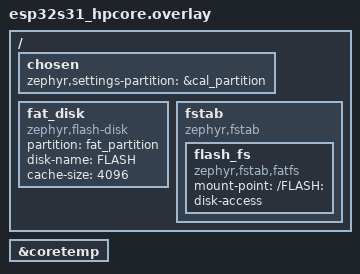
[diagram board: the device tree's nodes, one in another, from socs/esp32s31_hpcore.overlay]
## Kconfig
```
# SPDX-License-Identifier: GPL-3.0-or-later

mainmenu "multiapp: one firmware that runs the others"

config MULTIAPP_INSTR_HEAP_KB
	int "Extension code heap in PSRAM, KiB"
	default 1344

config MULTIAPP_DATA_HEAP_KB
	int "Extension data heap in PSRAM, KiB"
	default 1024
	help
	  The extensions' data, read-only data and bss, and llext's metadata.

config MULTIAPP_MODULE_HEAP_SIZE
	int "Internal RAM for the modules that run from it, bytes"
	default 8192 if SOC_SERIES_ESP32S31
	default 35840
	help
	  IRAM_ATTR code, data and bss of the modules built INTERNAL: below ring
	  bank 0 (src/apps.c), where a size that does not fit fails the host's
	  link. The Wi-Fi boots need the most: wifi and phy, about 33.4 KB. coex
	  also loads sdr (43 KB in all), which goes into dump bank 2 (BANK2,
	  doc/apps/multiapp-internals.md).

config MULTIAPP_MODULE_HIGH_HEAP_SIZE
	int "Bytes of the high region for a module's bss"
	# The ESP32-S31 has no high region: a token heap.
	default 256 if SOC_SERIES_ESP32S31
	default 14528
	help
	  The rest of the high region next to the area, for the bss of a module
	  built INTERNAL HIGH_BSS. A size that does not fit fails the host's link.

config MULTIAPP_MODULE_TESTS
	bool "The module loader's test modules"
	help
	  hello also needs hellolib in PSRAM, which needs hellofast in internal
	  RAM: the commands "hello mod" and "hello phy".

config MULTIAPP_STACK_SIZE
	int "Largest stack of an app's main() thread"
	default 4096
	help
	  One stack in PSRAM for every app's main(); an app that asks for more
	  (multiapp_extension() STACK) is refused.

# A default, not an assignment: the wifi module's Kconfig pass turns on what this depends on being off.
config ESP_SDR_PHY_ONLY
	default y

config MULTIAPP_SIGNED_EXTENSIONS
	bool "The sysbuild signs with the project's own key (SB_CONFIG_ESDR_SIGNING): extension files must be signed"
	depends on SOC_SERIES_ESP32S31
	help
	  Set by apps/common/sysbuild/signing.cmake. Then a key the build cannot use for the extension
	  signatures (not ED25519, unreadable) stops the build: accepting unsigned extensions in a build whose
	  image is signed would make the signature check a decoration.

config MULTIAPP_UNLOAD
	bool "Switch apps in place, unloading the running one"
	default y if SOC_SERIES_ESP32S3 || SOC_SERIES_ESP32S31
	select THREAD_MONITOR
	select SYS_HEAP_RUNTIME_STATS
	help
	  "multiapp run" stops the running app, unloads it and the modules the next one does not
	  need (the Wi-Fi driver, the SDR) and loads the next, when the two boots are compatible
	  (same USB profile, no console app). Otherwise, and when anything refuses to stop, it
	  reboots into the next app. Exercised on hardware on the ESP32-S3; the ESP32-S31 builds
	  with it, its radio module's down path is not yet tried on a board.

config MULTIAPP_STOP_TIMEOUT_MS
	int "How long an app's main() may take to end before the switch gives up"
	default 5000
	depends on MULTIAPP_UNLOAD

config MULTIAPP_STAGES
	bool "Hot-swap a DSP stage of the running app (development)"
	default y if SOC_SERIES_ESP32S3 || SOC_SERIES_ESP32S31
	depends on MULTIAPP_UNLOAD
	help
	  An app declares stages (include/multiapp/stage.h, MULTIAPP_STAGE_DEFINE()); "multiapp stage"
	  loads a small kernel (multiapp_kernel() in CMakeLists.txt, a file uploaded over the shell
	  or read from the volume) into the running app and swaps one stage to it at the app's
	  quiescent point, then unloads the old kernel, all without a reboot
	  (doc/apps/multiapp-internals.md, "Hot-swapping a stage"; apps/multiapp/scripts/kswap.py).
	  A development feature: it runs code of your choosing, so it belongs off in a product.

config MULTIAPP_STAGE_TIMEOUT_MS
	int "How long a swap waits for the app's sync point, ms"
	default 2000
	depends on MULTIAPP_STAGES
	help
	  After it the request is taken back, the new kernel unloaded and the shell says that the app
	  never got there. The shell commands take another value as a last argument.

config MULTIAPP_KERNEL_MAX_KB
	int "Largest kernel file, KiB"
	default 16
	depends on MULTIAPP_STAGES
	help
	  The PSRAM buffer an upload or a file is read into before llext copies it.

config MULTIAPP_KERNELS_IN_VOLUME
	bool "The kernels' files also go into the FAT volume image"
	depends on MULTIAPP_STAGES
	help
	  For "multiapp stage load" without a copy first; the kernels are never in multiapp_embedded[]
	  and never change the build id of the apps' files.

config MULTIAPP_WIFI
	bool "The stock Wi-Fi driver as a module"
	depends on DT_HAS_ESPRESSIF_ESP32_WIFI_ENABLED
	depends on ZEPHYR_HAL_ESPRESSIF_MODULE_BLOBS
	select WIFI
	select WIFI_USE_NATIVE_NETWORKING
	select NET_L2_WIFI_MGMT
	select NET_L2_ETHERNET_MGMT
	select THREAD_CUSTOM_DATA
	select EVENTS
	select THREAD_STACK_INFO
	help
	  The driver and its blobs are a module, wifi.llext on the volume, which
	  only the boots of an app that needs it load. The host has its
	  network interface (src/wifi_netif.c), down in every other boot, and
	  what the driver needs from the kernel and the network stack.

config MULTIAPP_MICROPYTHON
	bool "MicroPython as an app"
	depends on ZEPHYR_MICROPYTHON_MODULE
	help
	  The port, its C modules and frozen Python are one extension,
	  micropython.llext on the volume (micropython.cmake). The host keeps
	  what they need from the kernel, /FLASH: and the USB device; "multiapp
	  run micropython" reboots into its REPL on the CDC-ACM port.

config MULTIAPP_MICROPYTHON_GUI
	bool "MicroPython with a display"
	depends on MULTIAPP_MICROPYTHON
	help
	  Its extension also builds LVGL and the drivers of the board's display,
	  input devices and SD card, and freezes the launcher's apps. The
	  devicetree must have the board's peripherals; the host has no driver
	  for them.

config MULTIAPP_OSMOSDR_HS_LOAD_LOG
	bool "osmosdr_hs logs the CPU its stream leaves (a bench)"
	depends on SOC_SERIES_ESP32S31
	help
	  osmosdr_hs with its loadlog.conf, as its standalone bench build: a low
	  priority thread counts what it gets, and the log has it every 10 s.

config MULTIAPP_EMBEDDED
	bool "Apps built into the image too"
	default y
	help
	  Each app is also built into the image, loaded when the FAT volume has
	  no good file for it. Without, an app runs only from its file.

config MULTIAPP_FILE_MAX_KB
	int "Largest app file, KiB"
	default 2048
	help
	  The PSRAM buffer a boot reads the app's file into before loading it.

config MULTIAPP_AREA_SIZE
	int "Bytes of internal RAM the apps share, one per boot"
	# No app on the ESP32-S31 has buffers in the area.
	default 16 if SOC_SERIES_ESP32S31
	default 24128
	help
	  In the high region: the buffers an app defines with
	  ESP_SDR_HIGH_BUF_DEFINE() and ESP_SDR_HIGH_STACK_DEFINE() (osmosdr's
	  USB blocks, ring and USB thread stacks), or in other boots the 802.15.4
	  driver's buffers.

config MULTIAPP_RUNNING_AFTER_MS
	int "Mark an app as running once its main() has run this long, ms"
	default 3000
	help
	  A boot that dies on the way to its app is skipped once, to end a crash loop: the record of how
	  far it got (src/apps.c) says "running" when main() returns. An app whose main() never
	  returns (osmosdr_hs) would stay "in main" for ever, and a warm reboot would skip its autostart
	  once. This many milliseconds after main() starts, with the app still the one that started,
	  the record says "running" too; an app that dies earlier stays a crash-loop suspect. 0:
	  only when main() returns.

config MULTIAPP_AUTOSTART
	string "App to start at boot"
	default ""
	help
	  Started when no "multiapp run" request is pending from before a reset.
	  Empty: none, start one with "multiapp run <name>".

config LLEXT_EXPORT_SYMBOL_GROUP_MULTIAPP
	def_bool y
	help
	  What the embedded extensions import, exported by exports.py. Zephyr's
	  default groups (every syscall, a libc subset) stay off: what they
	  export is kept by the linker, kernel code in IRAM included.

# USB shell and DFU.
rsource "../common/Kconfig"
source "samples/subsys/usb/common/Kconfig.sample_usbd"

source "Kconfig.zephyr"
```

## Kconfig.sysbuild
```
# SPDX-License-Identifier: GPL-3.0-or-later

# The own signing key defaults (the ESP32-S31 CoreBoard), ahead of sysbuild's.
rsource "../common/sysbuild/Kconfig.signing"

source "share/sysbuild/Kconfig"
```

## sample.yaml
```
sample:
  name: ESP-SDR multiapp
  description: >-
    One firmware that runs the other apps as loadable extensions
    (doc/apps/multiapp-internals.md): capture, rfprobe, wpan, stream, osmosdr and link,
    loaded from files on a FAT volume, with built-in copies
common:
  tags: esp-sdr
  sysbuild: true
  # Each scenario names its integration board: twister would add a list here to every scenario's,
  # and the S31 one cannot have the XIAO.
tests:
  # The console is on USB CDC-ACM; "multiapp run <name>" there (see README).
  sample.esp_sdr.multiapp:
    platform_allow:
      - xiao_esp32s3/esp32s3/procpu
      - communicator_badge/esp32s3/procpu
      - esp32s31_function_coreboard/esp32s31/hpcore
    build_only: true
    integration_platforms:
      - xiao_esp32s3/esp32s3/procpu
  # On the desk with the boards attached (pytest/test_multiapp.py): the image and
  # its FAT volume (scripts/twister-flash.py), booting into hello from its file.
  sample.esp_sdr.multiapp.hil:
    platform_allow:
      - xiao_esp32s3/esp32s3/procpu
      - communicator_badge/esp32s3/procpu
    harness: pytest
    harness_config:
      pytest_dut_scope: module
      pytest_root:
        - pytest/test_multiapp.py
    extra_args:
      - multiapp_EXTRA_CONF_FILE=hil.conf
    integration_platforms:
      - xiao_esp32s3/esp32s3/procpu
    timeout: 600
  # The same, booting into wifitest (pytest/test_wifi.py). Needs an access point in range.
  sample.esp_sdr.multiapp.wifi.hil:
    platform_allow:
      - xiao_esp32s3/esp32s3/procpu
      - communicator_badge/esp32s3/procpu
    harness: pytest
    harness_config:
      pytest_dut_scope: module
      pytest_root:
        - pytest/test_wifi.py
    extra_args:
      - multiapp_EXTRA_CONF_FILE=hil-wifi.conf
    integration_platforms:
      - xiao_esp32s3/esp32s3/procpu
    timeout: 600
  # The same, booting into micropython (pytest/test_micropython.py), which then has the REPL.
  sample.esp_sdr.multiapp.micropython.hil:
    platform_allow:
      - xiao_esp32s3/esp32s3/procpu
      - communicator_badge/esp32s3/procpu
    harness: pytest
    harness_config:
      pytest_dut_scope: module
      pytest_root:
        - pytest/test_micropython.py
    extra_args:
      - multiapp_EXTRA_CONF_FILE=hil-micropython.conf
    integration_platforms:
      - xiao_esp32s3/esp32s3/procpu
    timeout: 600
  # On the ESP32-S31-Function-CoreBoard-1, its USB HS port on the PC (pytest/test_multiapp_s31.py):
  # the board's own configuration, booting into osmosdr_hs from its file.
  sample.esp_sdr.multiapp.s31.hil:
    platform_allow:
      - esp32s31_function_coreboard/esp32s31/hpcore
    harness: pytest
    harness_config:
      pytest_dut_scope: module
      pytest_root:
        - pytest/test_multiapp_s31.py
    integration_platforms:
      - esp32s31_function_coreboard/esp32s31/hpcore
    timeout: 600
```

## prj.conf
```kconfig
# The radio without the Wi-Fi driver, as modules the host loads for the apps that need it.
CONFIG_ESP_SDR=y
CONFIG_ESP_SDR_AS_EXTENSION=y
# stream's network stack, and the packets of the 802.15.4 driver.
CONFIG_NETWORKING=y

CONFIG_SHELL=y
CONFIG_LOG=y
CONFIG_LOG_MODE_DEFERRED=y

# Loadable extensions, code and data in PSRAM heaps (src/apps.c).
CONFIG_LLEXT=y
CONFIG_LLEXT_HEAP_DYNAMIC=y
# A module may run from internal RAM (src/apps.c).
CONFIG_LLEXT_REGION_HEAPS=y
# Every global of an extension, not only EXPORT_SYMBOL()s: the host finds the
# hooks an app defines by name (app_usb_dfu_prepare()).
CONFIG_LLEXT_IMPORT_ALL_GLOBALS=y
# The host exports exactly what its extensions import (exports.py, group MULTIAPP).
CONFIG_LLEXT_EXPORT_DEFAULT_GROUPS=n
CONFIG_LLEXT_LOG_LEVEL_ERR=y

# What the apps need from the host: capture's float output, rfprobe's dumps.
CONFIG_PICOLIBC_IO_FLOAT=y
CONFIG_BASE64=y
```

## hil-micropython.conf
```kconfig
# sample.esp_sdr.multiapp.micropython.hil: the boot runs micropython, which has no built-in copy.
CONFIG_MULTIAPP_AUTOSTART="micropython"
```

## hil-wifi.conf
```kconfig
# sample.esp_sdr.multiapp.wifi.hil: the boot runs wifitest, whose module has no built-in copy.
CONFIG_MULTIAPP_AUTOSTART="wifitest"
```

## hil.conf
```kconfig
# The desk check (sample.esp_sdr.multiapp.hil): every boot starts hello.
CONFIG_MULTIAPP_AUTOSTART="hello"
# The module loader's checks: hello needs hellolib and hellofast, and the PHY's blobs.
CONFIG_MULTIAPP_MODULE_TESTS=y
```

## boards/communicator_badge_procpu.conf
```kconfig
# The Hackaday Communicator with its display and keyboard: MicroPython with LVGL (micropython.cmake), whose
# drivers are in its extension.
CONFIG_MULTIAPP_MICROPYTHON_GUI=y
# Comes up as the badge it is: the launcher on the panel, also after a power cycle. A bad file falls back to a
# boot without an app, with the drive.
CONFIG_MULTIAPP_AUTOSTART="micropython"
```

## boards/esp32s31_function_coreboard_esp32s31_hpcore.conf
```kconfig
# The ESP32-S31-Function-CoreBoard-1 boots into osmosdr_hs, the SDR on its USB HS port, also after a
# power cycle; the shell's "multiapp run <name>" starts another app until the next reset. A bad
# file falls back to the built-in copy, else to a boot without an app, with the drive.
CONFIG_MULTIAPP_AUTOSTART="osmosdr_hs"
```

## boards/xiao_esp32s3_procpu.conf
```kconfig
# The XIAO ESP32S3 with its display, knob and SD card: MicroPython with LVGL (micropython.cmake), whose
# drivers are in its extension. What the host keeps for it:
CONFIG_MULTIAPP_MICROPYTHON_GUI=y
# Boots to MicroPython's launcher (the apps on the panel, the knob picks), as the Communicator does,
# also after a power cycle; the shell's "multiapp run <name>" (esdr.shell() from the REPL) starts
# another app. A bad file falls back to a boot without an app, with the drive.
CONFIG_MULTIAPP_AUTOSTART="micropython"
# On by default with the nodes in the devicetree, and SPI with it: only in the extension.
CONFIG_DISK_DRIVER_SDMMC=n
# Two USB drives: the volume and the SD card, which it may hold in exFAT.
CONFIG_USBD_MSC_LUNS_PER_INSTANCE=2
CONFIG_FS_FATFS_EXFAT=y
# The SD card path (disk, SD stack, SPI driver) is deeper than the flash disk's.
CONFIG_USBD_MSC_STACK_SIZE=1728
```

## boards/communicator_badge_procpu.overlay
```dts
/*
 * SPDX-License-Identifier: GPL-3.0-or-later
 *
 * The Hackaday Communicator's display and keyboard: drivers only in the micropython extension.
 */

#include "../../micropython/boards/communicator_badge_periph.dtsi"
```

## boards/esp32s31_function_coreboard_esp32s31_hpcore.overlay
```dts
/*
 * SPDX-License-Identifier: GPL-3.0-or-later
 *
 * The ESP32-S31-Function-CoreBoard-1's USB 2.0 OTG HS port, its USB-A socket J4: the shell on a
 * CDC-ACM port, the drive (also while an app runs), DFU and osmosdr_hs's stream. Its VBUS is
 * driven whenever the board has power: connect it with VBUS cut (apps/osmosdr_hs/README.rst). The
 * console stays on UART0.
 */

/ {
	chosen {
		zephyr,shell-uart = &cdc_acm_uart0;
	};
};

zephyr_udc0: &usb_otg {
	status = "okay";

	/*
	 * A FIFO per IN endpoint, in the order the classes take them (first fit, in the order CDC-ACM,
	 * DFU, the vendor class, the drive): CDC-ACM's notification (EP1, 16 words: interrupt only) and
	 * data (EP2), then osmosdr_hs's stream (EP3: at least 256 words, apps/osmosdr_hs's overlay) and
	 * the drive (EP4: 128 words, one 512-byte bulk packet, the least a bulk IN endpoint has). A boot
	 * without osmosdr_hs gives the drive EP3. With RX (256) and EP0 (32) the 608 words below make
	 * the 896 the controller has (GHWCFG3), none left over.
	 */
	g-tx-fifo-size = <16 128 288 128 16 16 16>;

	cdc_acm_uart0: cdc_acm_uart0 {
		compatible = "zephyr,cdc-acm-uart";
		label = "ESP-SDR multiapp shell";
	};
};
```

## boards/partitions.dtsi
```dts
/*
 * SPDX-License-Identifier: GPL-3.0-or-later
 *
 * Flash layout of multiapp, for the application and its MCUboot
 * (sysbuild/mcuboot.overlay), which must agree on it: Espressif's 4 MB AMP
 * table, the XIAO ESP32S3's own, on any S3 board, and the 4 MB above it as
 * the FAT volume, where west dfu --esptool, nix/collect.py and the release
 * workflow expect it.
 */

&flash0 {
	/delete-node/ partitions;
};

#include <espressif/partitions_0x0_amp.dtsi>

&flash0 {
	partitions {
		fat_partition: partition@400000 {
			compatible = "zephyr,mapped-partition";
			label = "fat";
			reg = <0x400000 DT_SIZE_M(4)>;
		};
	};
};
```

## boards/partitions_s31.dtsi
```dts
/*
 * SPDX-License-Identifier: GPL-3.0-or-later
 *
 * Flash layout of multiapp on a 16 MB ESP32-S31 board, for the application and its MCUboot
 * (sysbuild/mcuboot_s31.overlay), which must agree on it: MCUboot at 0x2000 and the application in
 * the lower 8 MB (Espressif's 8 MB table: two 3840 KiB slots), the upper 8 MB the FAT volume, as
 * apps/micropython has it on these chips. The crystal calibration has a partition of its own in
 * the table's free space (settings on ZMS), so that the device never writes the FAT volume, which
 * the PC may have as a USB drive.
 */

&flash0 {
	/delete-node/ partitions;
};

#include <espressif/partitions_0x2000_default_8M.dtsi>

&flash0 {
	partitions {
		/*
		 * 16 KiB, four erase sectors, right after Espressif's 192 KiB "storage" (which ends at
		 * 0x7e0000) and below the coredump at 0x7ff000: the table leaves 124 KiB there unused.
		 */
		cal_partition: partition@7e0000 {
			compatible = "zephyr,mapped-partition";
			label = "calibration";
			reg = <0x7e0000 DT_SIZE_K(16)>;
		};

		fat_partition: partition@800000 {
			compatible = "zephyr,mapped-partition";
			label = "fat";
			reg = <0x800000 DT_SIZE_M(8)>;
		};
	};
};
```

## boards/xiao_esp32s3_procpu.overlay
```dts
/*
 * SPDX-License-Identifier: GPL-3.0-or-later
 *
 * The XIAO ESP32S3's display, knob and SD card: drivers only in the micropython extension.
 */

#include "../../micropython/boards/xiao_esp32s3_periph.dtsi"
```

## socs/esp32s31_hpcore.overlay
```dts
/*
 * SPDX-License-Identifier: GPL-3.0-or-later
 *
 * multiapp on the ESP32-S31: the apps as files on the FAT volume. The board's overlay puts the
 * shell on a CDC-ACM port of its USB connector.
 */

/ {
	chosen {
		/* The crystal calibration (esp_sdr/cal): settings on ZMS in a partition of its own. */
		zephyr,settings-partition = &cal_partition;
	};

	/* The apps as files: the FAT volume, block device "FLASH". */
	fat_disk: fat_disk {
		compatible = "zephyr,flash-disk";
		partition = <&fat_partition>;
		disk-name = "FLASH";
		cache-size = <4096>;
	};

	fstab {
		compatible = "zephyr,fstab";

		flash_fs: flash_fs {
			compatible = "zephyr,fstab,fatfs";
			mount-point = "/FLASH:";
			disk-access;
		};
	};
};

/* The die temperature for osmosdr_hs's crystal calibration (apps/common/dietemp.overlay). */
&coretemp {
	status = "okay";
};

#include "../boards/partitions_s31.dtsi"
```

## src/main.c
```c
/*
 * SPDX-License-Identifier: GPL-3.0-or-later
 *
 * multiapp host (doc/apps/multiapp-internals.md): the USB shell and DFU, the radio, and the
 * apps built as extensions (apps.c).
 */

#include <zephyr/app_version.h>
#include <zephyr/kernel.h>

#include "app_cpu.h"
#include "app_usb.h"
#include "apps.h"

int main(void)
{
	printk("multiapp %s\n", APP_VERSION_STRING);
	/*
	 * Before USB and the watchdog, whose interrupts land on the CPU that allocates them: CPU 1 is
	 * the radio's, whose ring masks interrupts. This thread could otherwise come back on it from
	 * anything that makes it wait, such as stopping the shell (src/apps.c).
	 */
	app_cpu_pin_system_threads(0);
	app_cpu_pin_self(0);
	/*
	 * The files while the flash is the host's alone, then the app and the modules it needs, the
	 * radio among them, before USB, whose classes call its handlers (osmosdr's).
	 */
	(void)multiapp_drive_scan();
	/* Without an app (none asked for, or it failed) the PC still has the volume as a USB drive. */
	(void)multiapp_boot();
	/* The USB shell and DFU, and the trial watchdog that reverts an image that hangs. */
	if (app_usb_init() != 0) {
		printk("multiapp: usb init failed\n");
	}
	multiapp_usb_up();
	multiapp_note_main_stack();
	return 0;
}
```

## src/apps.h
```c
/*
 * SPDX-License-Identifier: GPL-3.0-or-later
 */

#ifndef MULTIAPP_APPS_H_
#define MULTIAPP_APPS_H_

#include <stdbool.h>
#include <stddef.h>
#include <stdint.h>
#include <sys/types.h>

#include <zephyr/device.h>

/* Where an extension's code and data go; its symbol tables stay in PSRAM. */
enum multiapp_place {
	MULTIAPP_PLACE_PSRAM,
	/* Its IRAM_ATTR code, data and bss below bank 0, the rest in PSRAM (ext/module_fast.ld). */
	MULTIAPP_PLACE_INTERNAL,
	/* As MULTIAPP_PLACE_INTERNAL, its bss in the high region. */
	MULTIAPP_PLACE_INTERNAL_HIGH_BSS,
};

/* An extension built with this image (embedded.c, generated by CMakeLists.txt). */
struct multiapp_embedded {
	const char *name;
	/* Its file (the ELF and its trailer), NULL without CONFIG_MULTIAPP_EMBEDDED. */
	const uint8_t *elf;
	size_t size;
	/* MULTIAPP_USB_*: the USB classes it needs. */
	uint32_t usb;
	/* Whether it has buffers in multiapp_area, which it then owns for the boot. */
	bool area;
	/* A module: code other extensions call, loaded before them, no main(). */
	bool module;
	/* Where its code and data go. */
	enum multiapp_place place;
	/* A module with devices: the host runs its init table as it loads it. */
	bool devices;
	/* It takes the CDC-ACM port from the shell, and its main() starts with USB up. */
	bool console;
	/* SRAM dump bank 2 is the boot's second module heap, and the SDR leaves it alone. */
	bool bank2;
	/* The modules to load before it, NULL-terminated. */
	const char *const *requires;
};

extern const struct multiapp_embedded multiapp_embedded[];
extern const size_t multiapp_embedded_count;

const struct multiapp_embedded *multiapp_embedded_find(const char *name);

/* Load @p name and start its main(); -EBUSY once an app is loaded. */
int multiapp_start(const char *name);

/*
 * The per-extension path, for what loads or unloads one module into a running app (the kernel swap
 * of doc/apps/multiapp-internals.md). A module is loaded with the modules it REQUIRES, its
 * constructors and its multiapp_module_up(), and unloaded with its multiapp_module_down(), its
 * destructors, a sweep of the threads it left in its regions, its shell roots and its regions,
 * after the use count says nothing else imports from it.
 *
 * Both are for the shell's thread (they take the loader's data). Loading an extension that is
 * loaded returns 0. Unloading returns -EBUSY when another extension imports from it or its down
 * hook refuses, -ENOENT when it is not loaded; then it is as it was, apart from what its down
 * hook had stopped.
 */
int multiapp_module_load(const char *name);
int multiapp_module_unload(const char *name);

/* USB has started: the main() of an app that wanted that runs now. */
void multiapp_usb_up(void);

/*
 * Start @p name now, or (returns 1) reboot into it: when an app is loaded or
 * USB runs another profile.
 */
int multiapp_request(const char *name);

/* At boot: start the app a request or CONFIG_MULTIAPP_AUTOSTART names; true if one runs. */
bool multiapp_boot(void);

/* A global function of the loaded app, by name (its hooks), or NULL; NULL once it is unloading. */
void *multiapp_app_fn(const char *name);

/*
 * The app is unloading (multiapp_app_fn() finds nothing now): forget the handlers src/osmosdr.c
 * found in it and wait for the USB thread to leave the ones it is in. 0, or -EBUSY if one does not
 * return (the app's memory must stay then).
 */
int multiapp_osmosdr_drop(void);

/* What an app's app_usb_init() calls: nothing to do (include/multiapp/ext.h). */
int multiapp_ext_usb_init(void);

/* What an extension's device_get_binding() calls (include/multiapp/ext.h). */
const struct device *multiapp_device_get_binding(const char *name);

/* Measure main()'s stack use as it returns, for "multiapp info". */
void multiapp_note_main_stack(void);

/*
 * The apps as files on the FAT volume (drive.c). Only at boot, before USB
 * starts and before an app runs (its buffers are in bank 0).
 */
/* Mount, look up and check every built-in app's file, unmount; 0 or -errno (no volume). */
int multiapp_drive_scan(void);
/* The scan's result: 0, or why there is no volume. */
int multiapp_drive_status(void);
/* What the scan found for @p name: its size (or -errno) and whether it equals the built-in one. */
int multiapp_drive_file(const char *name, ssize_t *size, bool *same);
/* Hand the volume to the PC over USB (a boot without an app): ready the disk. */
int multiapp_drive_export(void);
/*
 * Whether the PC holds the volume as a USB drive: multiapp_drive_write_begin() refuses then.
 * multiapp_drive_export() sets it; the boots that run an app while MSC is registered will set and
 * clear it as the PC takes the medium and gives it back.
 */
void multiapp_drive_msc_set(bool exported);
/* Mount the volume read-write for the boot's app, its files read through it: 0 or -errno. */
int multiapp_drive_mount_rw(void);

/* The USB drives go through the disks the boot's app registers (src/drive.c). */
void multiapp_drive_app_disks(void);
/* Read @p name's file into @p buf: its size, or -errno. */
ssize_t multiapp_drive_read(const char *name, uint8_t *buf, size_t max);

#endif /* MULTIAPP_APPS_H_ */
```

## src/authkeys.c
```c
/*
 * SPDX-License-Identifier: GPL-3.0-or-later
 *
 * See authkeys.h.
 */

#include <errno.h>
#include <string.h>

#include "authkeys.h"

/* ---- SHA-256 (FIPS 180-4) ---- */

static const uint32_t K256[64] = {
	0x428a2f98, 0x71374491, 0xb5c0fbcf, 0xe9b5dba5, 0x3956c25b, 0x59f111f1, 0x923f82a4, 0xab1c5ed5,
	0xd807aa98, 0x12835b01, 0x243185be, 0x550c7dc3, 0x72be5d74, 0x80deb1fe, 0x9bdc06a7, 0xc19bf174,
	0xe49b69c1, 0xefbe4786, 0x0fc19dc6, 0x240ca1cc, 0x2de92c6f, 0x4a7484aa, 0x5cb0a9dc, 0x76f988da,
	0x983e5152, 0xa831c66d, 0xb00327c8, 0xbf597fc7, 0xc6e00bf3, 0xd5a79147, 0x06ca6351, 0x14292967,
	0x27b70a85, 0x2e1b2138, 0x4d2c6dfc, 0x53380d13, 0x650a7354, 0x766a0abb, 0x81c2c92e, 0x92722c85,
	0xa2bfe8a1, 0xa81a664b, 0xc24b8b70, 0xc76c51a3, 0xd192e819, 0xd6990624, 0xf40e3585, 0x106aa070,
	0x19a4c116, 0x1e376c08, 0x2748774c, 0x34b0bcb5, 0x391c0cb3, 0x4ed8aa4a, 0x5b9cca4f, 0x682e6ff3,
	0x748f82ee, 0x78a5636f, 0x84c87814, 0x8cc70208, 0x90befffa, 0xa4506ceb, 0xbef9a3f7, 0xc67178f2,
};

#define ROR(x, n) (((x) >> (n)) | ((x) << (32 - (n))))

static void sha256_block(uint32_t h[8], const uint8_t *p)
{
	uint32_t w[64], a, b, c, d, e, f, g, hh;

	for (int i = 0; i < 16; i++) {
		w[i] = (uint32_t)p[4 * i] << 24 | (uint32_t)p[4 * i + 1] << 16 |
		       (uint32_t)p[4 * i + 2] << 8 | p[4 * i + 3];
	}
	for (int i = 16; i < 64; i++) {
		uint32_t s0 = ROR(w[i - 15], 7) ^ ROR(w[i - 15], 18) ^ (w[i - 15] >> 3);
		uint32_t s1 = ROR(w[i - 2], 17) ^ ROR(w[i - 2], 19) ^ (w[i - 2] >> 10);

		w[i] = w[i - 16] + s0 + w[i - 7] + s1;
	}
	a = h[0]; b = h[1]; c = h[2]; d = h[3]; e = h[4]; f = h[5]; g = h[6]; hh = h[7];
	for (int i = 0; i < 64; i++) {
		uint32_t t1 = hh + (ROR(e, 6) ^ ROR(e, 11) ^ ROR(e, 25)) + ((e & f) ^ (~e & g)) + K256[i] + w[i];
		uint32_t t2 = (ROR(a, 2) ^ ROR(a, 13) ^ ROR(a, 22)) + ((a & b) ^ (a & c) ^ (b & c));

		hh = g; g = f; f = e; e = d + t1; d = c; c = b; b = a; a = t1 + t2;
	}
	h[0] += a; h[1] += b; h[2] += c; h[3] += d; h[4] += e; h[5] += f; h[6] += g; h[7] += hh;
}

void ak_sha256(const uint8_t *data, size_t len, uint8_t out[32])
{
	uint32_t h[8] = {0x6a09e667, 0xbb67ae85, 0x3c6ef372, 0xa54ff53a,
			 0x510e527f, 0x9b05688c, 0x1f83d9ab, 0x5be0cd19};
	uint8_t tail[128];
	size_t full = len / 64, rem = len % 64, tail_len;
	uint64_t bits = (uint64_t)len * 8;

	for (size_t i = 0; i < full; i++) {
		sha256_block(h, data + 64 * i);
	}
	memset(tail, 0, sizeof(tail));
	if (rem != 0) {
		memcpy(tail, data + 64 * full, rem);
	}
	tail[rem] = 0x80;
	tail_len = rem < 56 ? 64 : 128;
	for (int i = 0; i < 8; i++) {
		tail[tail_len - 1 - i] = (uint8_t)(bits >> (8 * i));
	}
	sha256_block(h, tail);
	if (tail_len == 128) {
		sha256_block(h, tail + 64);
	}
	for (int i = 0; i < 8; i++) {
		out[4 * i] = (uint8_t)(h[i] >> 24);
		out[4 * i + 1] = (uint8_t)(h[i] >> 16);
		out[4 * i + 2] = (uint8_t)(h[i] >> 8);
		out[4 * i + 3] = (uint8_t)h[i];
	}
}

/* ---- base64 ---- */

static const char B64[] = "ABCDEFGHIJKLMNOPQRSTUVWXYZabcdefghijklmnopqrstuvwxyz0123456789+/";

static int b64_val(char c)
{
	if (c >= 'A' && c <= 'Z') {
		return c - 'A';
	}
	if (c >= 'a' && c <= 'z') {
		return c - 'a' + 26;
	}
	if (c >= '0' && c <= '9') {
		return c - '0' + 52;
	}
	return c == '+' ? 62 : c == '/' ? 63 : -1;
}

/* The decoded length, or -1 (not base64) or -2 (does not fit in @p max). Padding is optional. */
static int b64_decode(const char *s, size_t len, uint8_t *out, size_t max)
{
	size_t n = 0;
	uint32_t acc = 0;
	int bits = 0;

	while (len > 0 && s[len - 1] == '=') {
		len--;
	}
	if (len == 0 || len % 4 == 1) {
		return -1;
	}
	for (size_t i = 0; i < len; i++) {
		int v = b64_val(s[i]);

		if (v < 0) {
			return -1;
		}
		acc = (acc << 6) | (uint32_t)v;
		bits += 6;
		if (bits >= 8) {
			bits -= 8;
			if (n >= max) {
				return -2;
			}
			out[n++] = (uint8_t)(acc >> bits);
		}
	}
	return (int)n;
}

void ak_fingerprint(const uint8_t *blob, size_t len, char out[AK_FP_LEN])
{
	uint8_t d[32];
	size_t o = 0;

	ak_sha256(blob, len, d);
	memcpy(out, "SHA256:", 7);
	o = 7;
	for (size_t i = 0; i < 32; i += 3) {
		uint32_t v = (uint32_t)d[i] << 16 | (i + 1 < 32 ? (uint32_t)d[i + 1] << 8 : 0U) |
			     (i + 2 < 32 ? d[i + 2] : 0U);
		size_t chars = i + 2 < 32 ? 4 : 3; /* the last group: 2 bytes, 3 characters, no padding */

		for (size_t c = 0; c < chars; c++) {
			out[o++] = B64[(v >> (18 - 6 * c)) & 63U];
		}
	}
	out[o] = '\0';
}

/* ---- the wire blob of an RSA key: string "ssh-rsa", mpint e, mpint n ---- */

static bool rd_u32(const uint8_t *p, size_t len, size_t *off, uint32_t *v)
{
	if (len - *off < 4) {
		return false;
	}
	*v = (uint32_t)p[*off] << 24 | (uint32_t)p[*off + 1] << 16 | (uint32_t)p[*off + 2] << 8 | p[*off + 3];
	*off += 4;
	return true;
}

/* A string: points into @p p. */
static bool rd_str(const uint8_t *p, size_t len, size_t *off, const uint8_t **s, size_t *slen)
{
	uint32_t n;

	if (!rd_u32(p, len, off, &n) || n > len - *off) {
		return false;
	}
	*s = p + *off;
	*slen = n;
	*off += n;
	return true;
}

/* An unsigned big-endian number without its leading zeros. */
static void strip0(const uint8_t **s, size_t *n)
{
	while (*n > 0 && **s == 0) {
		(*s)++;
		(*n)--;
	}
}

static unsigned int bit_length(const uint8_t *s, size_t n)
{
	unsigned int b = 0;

	if (n == 0) {
		return 0;
	}
	for (uint8_t top = s[0]; top != 0; top >>= 1) {
		b++;
	}
	return (unsigned int)(n - 1) * 8U + b;
}

/* Type, e and n of an ssh-rsa blob, the numbers stripped. false: malformed. */
static bool rsa_parts(const uint8_t *blob, size_t len, const uint8_t **e, size_t *elen,
		      const uint8_t **n, size_t *nlen)
{
	const uint8_t *t;
	size_t off = 0, tlen;

	if (!rd_str(blob, len, &off, &t, &tlen) || tlen != 7 || memcmp(t, "ssh-rsa", 7) != 0 ||
	    !rd_str(blob, len, &off, e, elen) || !rd_str(blob, len, &off, n, nlen) || off != len) {
		return false;
	}
	strip0(e, elen);
	strip0(n, nlen);
	return *elen >= 1 && *elen <= 8 && *nlen >= 1;
}

/* ---- authorized_keys lines ---- */

static bool is_blank(char c)
{
	return c == ' ' || c == '\t';
}

static size_t token(const char *s, size_t len)
{
	size_t n = 0;

	while (n < len && !is_blank(s[n])) {
		n++;
	}
	return n;
}

static bool has_prefix(const char *s, size_t len, const char *prefix)
{
	size_t n = strlen(prefix);

	return len >= n && memcmp(s, prefix, n) == 0;
}

int ak_parse_line(const char *line, size_t len, struct ak_key *k)
{
	size_t n;
	int blob;

	memset(k, 0, sizeof(*k));
	while (len > 0 && (line[len - 1] == '\n' || line[len - 1] == '\r' || is_blank(line[len - 1]))) {
		len--;
	}
	while (len > 0 && is_blank(*line)) {
		line++;
		len--;
	}
	if (len == 0 || *line == '#') {
		return AK_SKIP;
	}
	/*
	 * No control bytes: the line is written to the key file as it is, and a newline in it (an exec command
	 * with a quoted \n) would make a second line that nothing has checked.
	 */
	for (size_t i = 0; i < len; i++) {
		unsigned char c = (unsigned char)line[i];

		if ((c < 0x20 && c != '\t') || c == 0x7f) {
			return AK_E_SYNTAX;
		}
	}
	n = token(line, len);
	if (!has_prefix(line, n, "ssh-") && !has_prefix(line, n, "ecdsa-sha2-") &&
	    !has_prefix(line, n, "sk-")) {
		/* command="...", from="...", restrict, no-pty: not honoured, so not accepted */
		return AK_E_OPTIONS;
	}
	if (n >= sizeof(k->type)) {
		return AK_E_SYNTAX;
	}
	memcpy(k->type, line, n);
	line += n;
	len -= n;
	while (len > 0 && is_blank(*line)) {
		line++;
		len--;
	}
	n = token(line, len);
	if (n == 0) {
		return AK_E_SYNTAX;
	}
	blob = b64_decode(line, n, k->blob, sizeof(k->blob));
	if (blob == -2) {
		return AK_E_SIZE;
	}
	if (blob < 0) {
		return AK_E_BLOB;
	}
	k->blob_len = (size_t)blob;
	line += n;
	len -= n;
	while (len > 0 && is_blank(*line)) {
		line++;
		len--;
	}
	if (len >= sizeof(k->comment)) {
		len = sizeof(k->comment) - 1;
	}
	memcpy(k->comment, line, len);

	/* The blob starts with the type again: a key of another type under this name is no key. */
	{
		const uint8_t *t;
		size_t off = 0, tlen;

		if (!rd_str(k->blob, k->blob_len, &off, &t, &tlen) || tlen != strlen(k->type) ||
		    memcmp(t, k->type, tlen) != 0) {
			return AK_E_BLOB;
		}
	}
	if (strcmp(k->type, "ssh-rsa") == 0) {
		const uint8_t *e, *m;
		size_t elen, mlen;

		/* Listed (with its size) but never used: this build has no RSA */
		k->kind = AK_KIND_RSA;
		if (!rsa_parts(k->blob, k->blob_len, &e, &elen, &m, &mlen)) {
			return AK_E_BLOB;
		}
		k->bits = bit_length(m, mlen);
		k->why = "RSA keys are not supported (use ssh-ed25519 or ecdsa-sha2-nistp256)";
		return 0;
	}
	if (strcmp(k->type, "ssh-ed25519") == 0) {
		const uint8_t *key;

		k->kind = AK_KIND_ED25519;
		if (ak_raw_pubkey(k, &key) < 0) {
			return AK_E_BLOB;
		}
		k->bits = 256;
		k->supported = true;
		return 0;
	}
	if (strcmp(k->type, "ecdsa-sha2-nistp256") == 0) {
		const uint8_t *key;

		k->kind = AK_KIND_ECDSA_P256;
		if (ak_raw_pubkey(k, &key) < 0) {
			return AK_E_BLOB;
		}
		k->bits = 256;
		k->supported = true;
		return 0;
	}
	k->why = "the server takes ssh-ed25519 and ecdsa-sha2-nistp256 keys only";
	return 0;
}

const char *ak_strerror(int err)
{
	switch (err) {
	case AK_E_SYNTAX:
		return "not a line of the form: <type> <base64 key> [comment]";
	case AK_E_OPTIONS:
		return "key options are not supported (a line starts with the key type)";
	case AK_E_BLOB:
		return "the key is malformed";
	case AK_E_SIZE:
		return "the key is too long";
	default:
		return "error";
	}
}

/* ---- raw keys ---- */

static uint8_t *put_u32(uint8_t *p, size_t v)
{
	*p++ = (uint8_t)(v >> 24);
	*p++ = (uint8_t)(v >> 16);
	*p++ = (uint8_t)(v >> 8);
	*p++ = (uint8_t)v;
	return p;
}

int ak_raw_pubkey(const struct ak_key *k, const uint8_t **raw)
{
	const uint8_t *t, *curve, *key;
	size_t off = 0, tlen, clen, klen;

	if (!rd_str(k->blob, k->blob_len, &off, &t, &tlen)) {
		return -EINVAL;
	}
	if (k->kind == AK_KIND_ED25519) {
		if (!rd_str(k->blob, k->blob_len, &off, &key, &klen) || off != k->blob_len ||
		    klen != AK_ED25519_KEY_LEN) {
			return -EINVAL;
		}
	} else if (k->kind == AK_KIND_ECDSA_P256) {
		if (!rd_str(k->blob, k->blob_len, &off, &curve, &clen) || clen != 8 ||
		    memcmp(curve, "nistp256", 8) != 0 || !rd_str(k->blob, k->blob_len, &off, &key, &klen) ||
		    off != k->blob_len || klen != AK_ECDSA_POINT_LEN || key[0] != 0x04) {
			return -EINVAL;
		}
	} else {
		return -EINVAL;
	}
	*raw = key;
	return (int)klen;
}

int ak_from_ecdsa_point(const uint8_t *point, size_t len, struct ak_key *k)
{
	uint8_t *p;

	memset(k, 0, sizeof(*k));
	if (len != AK_ECDSA_POINT_LEN || point[0] != 0x04) {
		return -EINVAL;
	}
	p = k->blob;
	p = put_u32(p, 19);
	memcpy(p, "ecdsa-sha2-nistp256", 19);
	p += 19;
	p = put_u32(p, 8);
	memcpy(p, "nistp256", 8);
	p += 8;
	p = put_u32(p, len);
	memcpy(p, point, len);
	p += len;
	k->blob_len = (size_t)(p - k->blob);
	strcpy(k->type, "ecdsa-sha2-nistp256");
	k->kind = AK_KIND_ECDSA_P256;
	k->bits = 256;
	k->supported = true;
	return 0;
}
```

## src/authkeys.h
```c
/*
 * SPDX-License-Identifier: GPL-3.0-or-later
 *
 * OpenSSH public keys for the SSH server (doc/dev/network-services.md, phase 3): the lines of an
 * authorized_keys file, the SHA-256 fingerprint OpenSSH prints, and the DER the server's key import
 * wants. No Zephyr here: tests/host/test_sshkeys.py builds it for the PC.
 *
 * The SSH server (subsys/net/lib/ssh) takes ecdsa-sha2-nistp256 and ssh-ed25519 keys from users and has
 * an ecdsa-sha2-nistp256 host key; the build has no RSA. A line of another type (ssh-rsa,
 * ecdsa-sha2-nistp384, sk-*, ssh-dss) parses, is listed with its fingerprint, and is marked unsupported.
 */

#ifndef MULTIAPP_AUTHKEYS_H_
#define MULTIAPP_AUTHKEYS_H_

#include <stdbool.h>
#include <stddef.h>
#include <stdint.h>

/* The longest key blob kept: an RSA key of 4096 bits is 535 bytes. */
#define AK_BLOB_MAX    600
#define AK_TYPE_MAX    40
#define AK_COMMENT_MAX 48
/* "SHA256:" and 43 characters of base64, and the NUL. */
#define AK_FP_LEN      51

/* What a key is, for the server's key import */
enum ak_kind {
	AK_KIND_OTHER,
	AK_KIND_RSA,
	AK_KIND_ECDSA_P256,
	AK_KIND_ED25519,
};

#define AK_ECDSA_POINT_LEN 65
#define AK_ED25519_KEY_LEN 32

struct ak_key {
	char type[AK_TYPE_MAX];       /* "ssh-rsa", "ssh-ed25519", "ecdsa-sha2-nistp256" */
	enum ak_kind kind;
	uint8_t blob[AK_BLOB_MAX];    /* the wire form: type, e, n for RSA */
	size_t blob_len;
	char comment[AK_COMMENT_MAX]; /* cut when longer */
	unsigned int bits;            /* RSA modulus bits (not used), 256 for the others */
	bool supported;               /* the server can use it */
	const char *why;              /* when not: the reason (static string) */
};

/* ak_parse_line() results besides 0 (a key) */
#define AK_SKIP     1             /* a blank line or a comment */
#define AK_E_SYNTAX (-1)          /* not "type base64 [comment]" */
#define AK_E_OPTIONS (-2)         /* a line with options (command=..., from=...): never honoured, so refused */
#define AK_E_BLOB   (-3)          /* the base64 or the blob inside is malformed or does not match the type */
#define AK_E_SIZE   (-4)          /* the blob is longer than AK_BLOB_MAX */

/*
 * One line of authorized_keys (CR, LF and trailing blanks are ignored). 0: @p k is filled (check
 * k->supported); AK_SKIP: nothing to do; else an AK_E_* error and @p k is not usable.
 */
int ak_parse_line(const char *line, size_t len, struct ak_key *k);

/* What went wrong, for a user: a static string. */
const char *ak_strerror(int err);

/* "SHA256:..." of @p blob, as ssh-keygen -lf prints it. @p out holds AK_FP_LEN bytes. */
void ak_fingerprint(const uint8_t *blob, size_t len, char out[AK_FP_LEN]);

/*
 * The raw public key of an ECDSA P-256 key (the 65 byte uncompressed point) or an Ed25519 key (32 bytes), as
 * ssh_keygen_import(..., SSH_HOST_KEY_FORMAT_RAW, ...) takes it: points into @p k. Its length, or -EINVAL.
 */
int ak_raw_pubkey(const struct ak_key *k, const uint8_t **raw);

/* The key of an uncompressed P-256 point (the host key's public part): the wire blob, for the fingerprint. */
int ak_from_ecdsa_point(const uint8_t *point, size_t len, struct ak_key *k);

/* SHA-256 (here for the fingerprint, so that the code needs no crypto library and builds on the PC). */
void ak_sha256(const uint8_t *data, size_t len, uint8_t out[32]);

#endif /* MULTIAPP_AUTHKEYS_H_ */
```

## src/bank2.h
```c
/*
 * SPDX-License-Identifier: GPL-3.0-or-later
 *
 * The capture bank as a second internal heap for the apps that do not capture (BANK2, apps.c):
 * ESP32-S3 dump bank 2, and on the ESP32-S31 TCM group 3 (0x2F060000), which the dump engine owns
 * only while it captures or starts the diagnostic bus (doc/dev/network-services.md, "Group 3").
 */

#ifndef MULTIAPP_BANK2_H_
#define MULTIAPP_BANK2_H_

#include <stdint.h>

#include <zephyr/sys/util.h>

extern uint8_t __esp_sdr_bank_start[], __esp_sdr_bank_end[];

#if defined(CONFIG_SOC_SERIES_ESP32S3)
#define MULTIAPP_BANK2 1
#define BANK2_START    __esp_sdr_bank_start
#define BANK2_SIZE     ((size_t)(__esp_sdr_bank_end - __esp_sdr_bank_start))
#elif defined(CONFIG_SOC_SERIES_ESP32S31)
#define MULTIAPP_BANK2 1
/*
 * The whole group up to the ROM boot stack (0x2F07AFB0, the ROM data is above it), not just the
 * engine's aperture (the bank proper, 0x1A010 bytes): the engine writes only the aperture, the rest
 * is memory like any, readable while the CPU is not parked (esp_sdr_s31.c group_take()).
 */
#define BANK2_GUARD 1024U
#define BANK2_START (__esp_sdr_bank_start + BANK2_GUARD)
#define BANK2_SIZE  ((size_t)(0x2F07AFB0U - (uintptr_t)BANK2_START))
#endif

#endif /* MULTIAPP_BANK2_H_ */
```

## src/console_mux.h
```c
/*
 * SPDX-License-Identifier: GPL-3.0-or-later
 *
 * The SSH server's callbacks (src/console_mux.c), which src/sshd.c passes to ssh_server_start().
 */

#ifndef MULTIAPP_CONSOLE_MUX_H_
#define MULTIAPP_CONSOLE_MUX_H_

#include <zephyr/net/ssh/server.h>

int cmux_server_event(struct ssh_server *sshd, const struct ssh_server_event *event, void *user_data);
int cmux_transport_event(struct ssh_transport *transport, const struct ssh_transport_event *event,
			 void *user_data);

/* Run @p fn on the sshd_work thread (src/sshd.c), one job at a time: 0 or -EBUSY. */
int sshd_run_job(void (*fn)(void *arg), void *arg);

/* Bytes of the server thread's stack never used, as of the last session's end (0: none yet). */
size_t cmux_server_stack_unused(void);

/* Milliseconds from a session's channel closing to its connection's slot being free, and from the stop of its shell
 * to the shell being free again, as of the last session (-1: none yet). */
void cmux_timing(int32_t *slot_ms, int32_t *shell_ms);

/* The server thread ended (src/sshd.c starts it again) */
void sshd_server_closed(void);

/* Sessions open now (shell and registered console), for `ssh status`; and whether the Zephyr shell is taken. */
int cmux_sessions(void);
bool cmux_shell_busy(void);

#endif /* MULTIAPP_CONSOLE_MUX_H_ */
```

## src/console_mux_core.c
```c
/*
 * SPDX-License-Identifier: GPL-3.0-or-later
 *
 * See console_mux_core.h.
 */

#include <errno.h>
#include <stddef.h>

#include "console_mux_core.h"

static const struct multiapp_console *repl;

int multiapp_console_register(const struct multiapp_console *c)
{
	int ret = 0;

	if (c == NULL || c->name == NULL || c->open == NULL || c->rx_ready == NULL || c->closed == NULL) {
		return -EINVAL;
	}
	cmux_lock();
	if (repl != NULL) {
		ret = -EBUSY;
	} else {
		repl = c;
	}
	cmux_unlock();
	return ret;
}

int multiapp_console_unregister(const struct multiapp_console *c)
{
	int ret = 0;

	cmux_lock();
	if (c == NULL || repl != c) {
		ret = -ENOENT;
	} else {
		repl = NULL;
		cmux_removed(c);
	}
	cmux_unlock();
	return ret;
}

const struct multiapp_console *cmux_current(void)
{
	return repl;
}

const struct multiapp_console *cmux_pick(enum cmux_request req)
{
	return req == CMUX_SHELL ? repl : NULL;
}
```

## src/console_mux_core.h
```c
/*
 * SPDX-License-Identifier: GPL-3.0-or-later
 *
 * The console registry and the choice of a session's console (no Zephyr: tests/host/test_sshkeys.py
 * builds it for the PC). The SSH glue is src/console_mux.c.
 */

#ifndef MULTIAPP_CONSOLE_MUX_CORE_H_
#define MULTIAPP_CONSOLE_MUX_CORE_H_

#include <multiapp/console.h>

/* What the client asked for */
enum cmux_request {
	CMUX_SHELL, /* a "shell" request: an interactive login */
	CMUX_EXEC,  /* an "exec" request: ssh <host> <command> */
};

/*
 * The console for a session: a registered one for a shell request, NULL (the Zephyr shell) for an exec
 * request and when none is registered. The caller holds the lock (cmux_lock()) until it has opened it.
 */
const struct multiapp_console *cmux_pick(enum cmux_request req);

/* The registered console or NULL */
const struct multiapp_console *cmux_current(void);

/* The glue's (the PC test's own stand-ins): one lock around pick and open, register and unregister. */
void cmux_lock(void);
void cmux_unlock(void);
/* @p c was unregistered: close its sessions (under the lock). */
void cmux_removed(const struct multiapp_console *c);

#endif /* MULTIAPP_CONSOLE_MUX_CORE_H_ */
```

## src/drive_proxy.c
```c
/*
 * SPDX-License-Identifier: GPL-3.0-or-later
 *
 * The device's claim on the FAT volume against the PC's USB drive: see drive_proxy.h. Compiled on
 * the host by tests/host/test_multiapp_drive.py as it is.
 */

#include <errno.h>

#include "drive_proxy.h"

void drive_proxy_init(struct drive_proxy *p, const struct drive_proxy_hooks *hooks)
{
	p->draining = false;
	p->claimed = false;
	p->hides = false;
	p->io = 0;
	/* No access has ended yet: a claim need not wait for a quiet period. */
	p->last_io = -(int64_t)DRIVE_QUIET_MS;
	p->hidden_at = 0;
	p->hold_until = 0;
	atomic_set(&p->hold, 0);
	atomic_set(&p->on_bus, 0);
	atomic_ptr_set(&p->busy, NULL);
	atomic_set(&p->busy_calls, 0);
	k_mutex_init(&p->vol);
	p->depth = 0;
	p->held = false;
	p->outer_write = false;
	p->hooks = *hooks;
}

void drive_proxy_on_bus(struct drive_proxy *p, bool on)
{
	atomic_set(&p->on_bus, on ? 1 : 0);
}

bool drive_proxy_is_on_bus(struct drive_proxy *p)
{
	return atomic_get(&p->on_bus) != 0;
}

void drive_proxy_set_busy(struct drive_proxy *p, bool (*busy)(void))
{
	atomic_ptr_set(&p->busy, (void *)busy);
	/* Taken back: the module's code may go as soon as no call of it is left. */
	for (int i = 0; busy == NULL && atomic_get(&p->busy_calls) != 0 && i < 1000; i++) {
		k_msleep(1);
	}
}

/* A call of the radio module's, counted in before the pointer is read. */
static bool ring_busy(struct drive_proxy *p)
{
	bool (*busy)(void);
	bool ret = false;

	atomic_inc(&p->busy_calls);
	busy = (bool (*)(void))atomic_ptr_get(&p->busy);
	if (busy != NULL) {
		ret = busy();
	}
	atomic_dec(&p->busy_calls);
	return ret;
}

/*
 * Whether the hold of a write is over, ending it when it is due: the 3 s have passed and no ring
 * runs. The ring is asked outside the lock (module code).
 */
static bool hold_over(struct drive_proxy *p)
{
	bool busy, over;
	k_spinlock_key_t key;

	if (atomic_get(&p->hold) == 0) {
		return true;
	}
	busy = ring_busy(p);
	key = k_spin_lock(&p->lock);
	if (k_uptime_get() >= p->hold_until && !busy) {
		atomic_set(&p->hold, 0);
	}
	over = atomic_get(&p->hold) == 0;
	k_spin_unlock(&p->lock, key);
	return over;
}

bool drive_proxy_visible(struct drive_proxy *p)
{
	bool over = hold_over(p);
	k_spinlock_key_t key = k_spin_lock(&p->lock);
	bool visible = over && !(p->hides && (p->draining || p->claimed));

	k_spin_unlock(&p->lock, key);
	return visible;
}

bool drive_proxy_io_begin(struct drive_proxy *p)
{
	int64_t start = k_uptime_get();

	for (;;) {
		bool over = hold_over(p);
		k_spinlock_key_t key = k_spin_lock(&p->lock);
		bool wait = false, ok = false;

		if (p->claimed) {
			/* A write has the volume: fail. A read has it: wait for its end. */
			wait = !p->hides;
		} else if (p->draining || over) {
			/* The command in flight may finish while a claim waits for its end. */
			ok = true;
			p->io++;
		}
		k_spin_unlock(&p->lock, key);
		if (ok) {
			return true;
		}
		if (!wait || k_uptime_get() - start >= DRIVE_GATE_MAX_MS) {
			return false;
		}
		k_msleep(DRIVE_POLL_MS);
	}
}

void drive_proxy_io_end(struct drive_proxy *p)
{
	k_spinlock_key_t key = k_spin_lock(&p->lock);

	p->io--;
	p->last_io = k_uptime_get();
	k_spin_unlock(&p->lock, key);
}

/* Wait for the PC's command to end (a write hides the medium meanwhile): 0, or -EBUSY with the state as it was. */
static int claim(struct drive_proxy *p, k_timepoint_t end, bool write)
{
	k_spinlock_key_t key = k_spin_lock(&p->lock);
	int64_t now = k_uptime_get();

	/* In a hold the period goes on, so that it counts from when the medium first went. */
	if (write && atomic_get(&p->hold) == 0) {
		p->hidden_at = now;
	}
	p->hides = write;
	p->draining = true;
	k_spin_unlock(&p->lock, key);

	for (;;) {
		key = k_spin_lock(&p->lock);
		now = k_uptime_get();
		if (p->io == 0U && now - p->last_io >= DRIVE_QUIET_MS) {
			p->draining = false;
			p->claimed = true;
			k_spin_unlock(&p->lock, key);
			return 0;
		}
		if (sys_timepoint_expired(end)) {
			p->draining = false;
			p->hides = false;
			k_spin_unlock(&p->lock, key);
			return -EBUSY;
		}
		k_spin_unlock(&p->lock, key);
		k_msleep(DRIVE_POLL_MS);
	}
}

/* The device is done: after a write the medium stays away until the period has lasted long enough. */
static void release(struct drive_proxy *p, bool write)
{
	k_spinlock_key_t key = k_spin_lock(&p->lock);
	int64_t until = p->hidden_at + DRIVE_HIDE_MIN_MS;

	p->claimed = false;
	p->hides = false;
	if (write) {
		if (until > p->hold_until) {
			p->hold_until = until;
		}
		atomic_set(&p->hold, 1);
	}
	k_spin_unlock(&p->lock, key);
}

int drive_take(struct drive_proxy *p, k_timeout_t timeout, bool write)
{
	k_timepoint_t end = sys_timepoint_calc(timeout);
	int ret = 0;

	if (p->hooks.in_usb_thread != NULL && p->hooks.in_usb_thread()) {
		return -EDEADLK;
	}
	if (k_mutex_lock(&p->vol, timeout) != 0) {
		return -EAGAIN;
	}
	if (p->depth > 0 && write && !p->outer_write) {
		/* A read cannot become a write: it did not hide the medium. */
		k_mutex_unlock(&p->vol);
		return -EDEADLK;
	}
	if (p->depth == 0) {
		p->outer_write = write;
		if (drive_proxy_is_on_bus(p)) {
			ret = claim(p, end, write);
			if (ret == 0 && p->hooks.remount != NULL) {
				ret = p->hooks.remount();
				if (ret != 0) {
					/* The volume may be in any state: a writer's PC reads it again. */
					release(p, write);
				}
			}
			if (ret != 0) {
				k_mutex_unlock(&p->vol);
				return ret;
			}
			p->held = true;
		}
	}
	p->depth++;
	return 0;
}

void drive_give(struct drive_proxy *p)
{
	if (--p->depth == 0 && p->held) {
		bool write = p->outer_write;

		p->held = false;
		if (write && p->hooks.sync != NULL) {
			p->hooks.sync();
		}
		release(p, write);
	}
	k_mutex_unlock(&p->vol);
}
```
